# MB9BF52xT register map
File version: 1.0
Registers are 32-bit, read-write, reset 0x0 unless marked. A register's access mark holds for its fields unless they carry their own. Offsets are from the block's base; [hi:lo] are bit positions; {n}, {i} and the like mark numbered series; 'fields as' and 'values as' point back to an identical list.

## GPIO — peripheral GPIO
Base 0x40033000
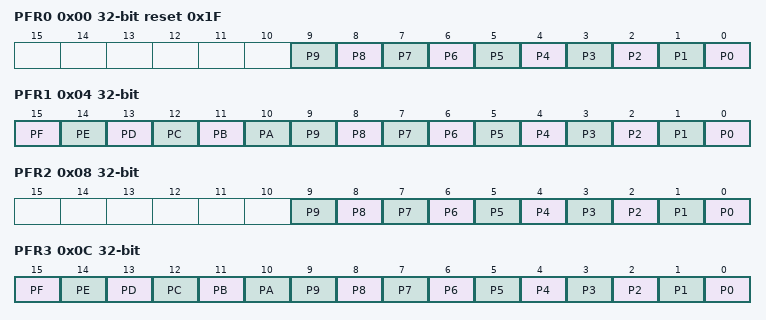
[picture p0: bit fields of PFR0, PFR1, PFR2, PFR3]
0x00 PFR0 reset 0x1F
  [n] P{n} (n=0..9)
0x04 PFR1
  [15] PF, [14] PE, [13] PD, [12] PC, [11] PB, [10] PA, [n] P{n} (n=0..9)
0x08 PFR2
  [n] P{n} (n=0..9)
0x0C PFR3
  fields as PFR1
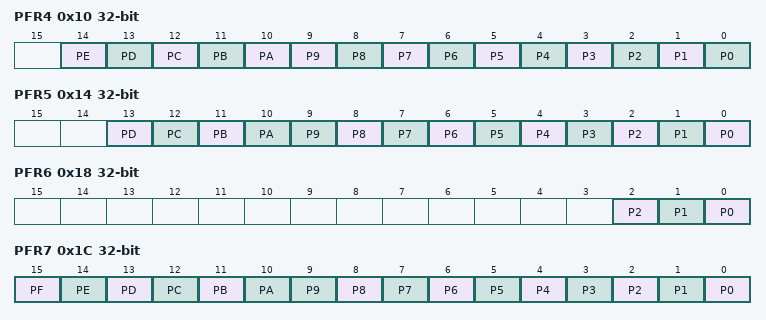
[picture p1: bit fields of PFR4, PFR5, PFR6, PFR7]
0x10 PFR4
  [14] PE, [13] PD, [12] PC, [11] PB, [10] PA, [n] P{n} (n=0..9)
0x14 PFR5
  [13] PD, [12] PC, [11] PB, [10] PA, [n] P{n} (n=0..9)
0x18 PFR6
  [2] P2, [1] P1, [0] P0
0x1C PFR7
  fields as PFR1
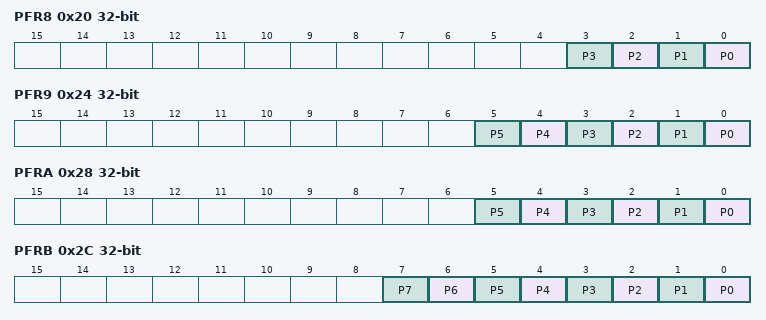
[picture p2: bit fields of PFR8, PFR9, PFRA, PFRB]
0x20 PFR8
  [n] P{n} (n=0..3)
0x24 PFR9
  [n] P{n} (n=0..5)
0x28 PFRA
  [n] P{n} (n=0..5)
0x2C PFRB
  [n] P{n} (n=0..7)
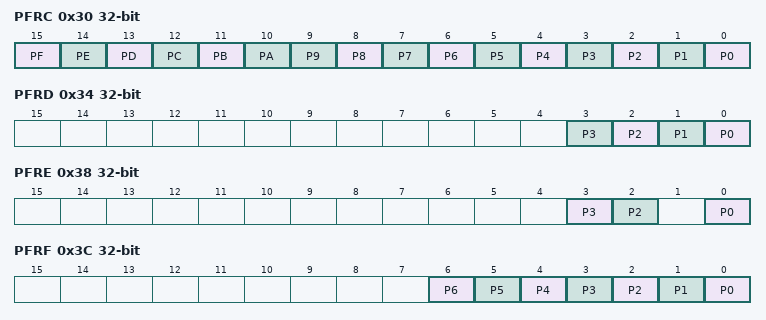
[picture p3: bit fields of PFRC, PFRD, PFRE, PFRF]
0x30 PFRC
  fields as PFR1
0x34 PFRD
  [n] P{n} (n=0..3)
0x38 PFRE (reset mask 0xB)
  [3] P3, [2] P2, [0] P0
0x3C PFRF
  [n] P{n} (n=0..6)
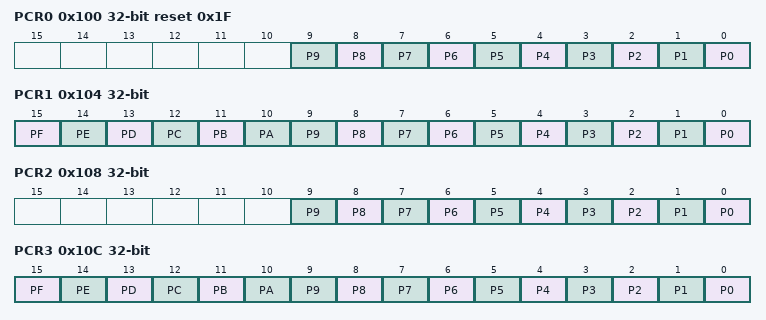
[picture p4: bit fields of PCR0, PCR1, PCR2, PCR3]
0x100 PCR0 reset 0x1F
  [n] P{n} (n=0..9)
0x104 PCR1
  fields as PFR1
0x108 PCR2
  [n] P{n} (n=0..9)
0x10C PCR3
  fields as PFR1
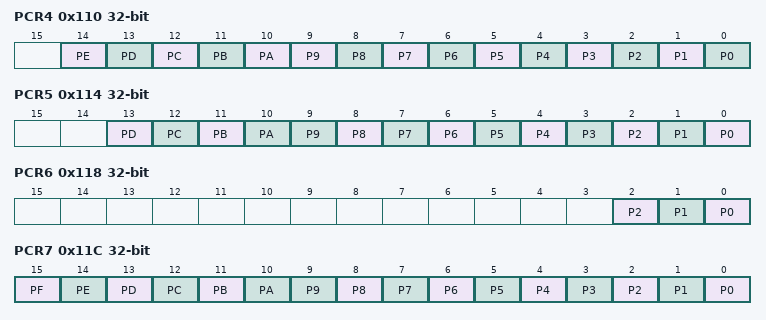
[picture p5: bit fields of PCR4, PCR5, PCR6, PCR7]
0x110 PCR4
  [14] PE, [13] PD, [12] PC, [11] PB, [10] PA, [n] P{n} (n=0..9)
0x114 PCR5
  [13] PD, [12] PC, [11] PB, [10] PA, [n] P{n} (n=0..9)
0x118 PCR6
  [2] P2, [1] P1, [0] P0
0x11C PCR7
  fields as PFR1
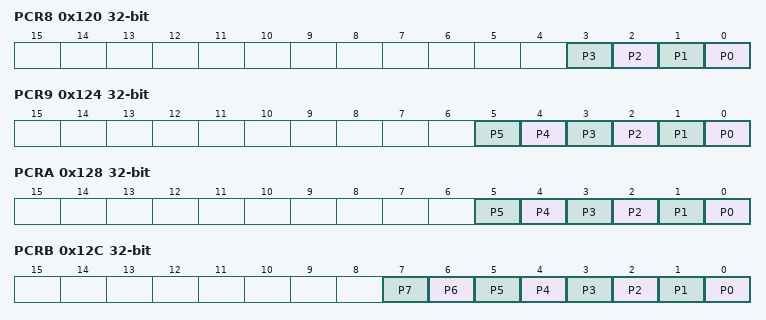
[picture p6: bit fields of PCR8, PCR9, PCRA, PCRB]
0x120 PCR8
  [n] P{n} (n=0..3)
0x124 PCR9
  [n] P{n} (n=0..5)
0x128 PCRA
  [n] P{n} (n=0..5)
0x12C PCRB
  [n] P{n} (n=0..7)
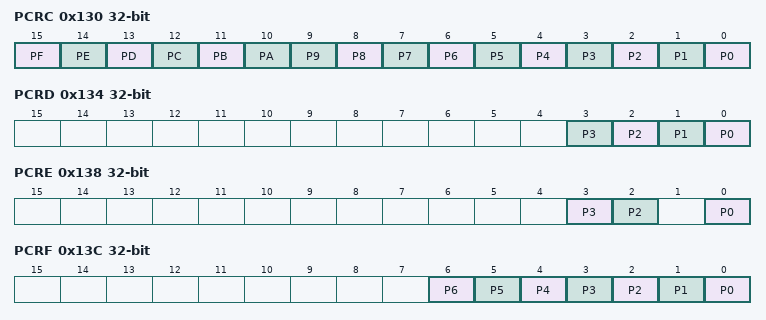
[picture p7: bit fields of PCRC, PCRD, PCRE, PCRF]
0x130 PCRC
  fields as PFR1
0x134 PCRD
  [n] P{n} (n=0..3)
0x138 PCRE (reset mask 0xB)
  [3] P3, [2] P2, [0] P0
0x13C PCRF
  [n] P{n} (n=0..6)
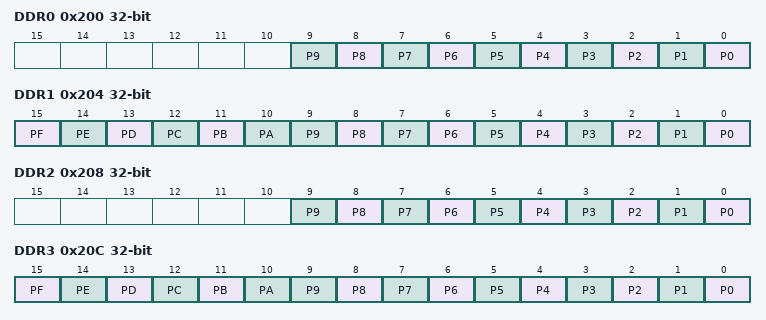
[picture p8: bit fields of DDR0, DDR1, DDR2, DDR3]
0x200 DDR0
  [n] P{n} (n=0..9)
0x204 DDR1
  fields as PFR1
0x208 DDR2
  [n] P{n} (n=0..9)
0x20C DDR3
  fields as PFR1
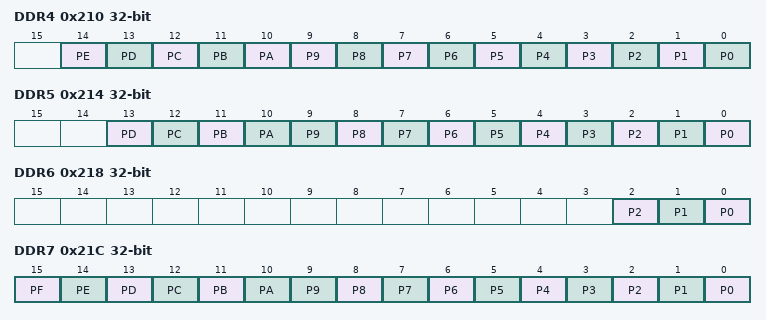
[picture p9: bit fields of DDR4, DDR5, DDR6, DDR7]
0x210 DDR4
  [14] PE, [13] PD, [12] PC, [11] PB, [10] PA, [n] P{n} (n=0..9)
0x214 DDR5
  [13] PD, [12] PC, [11] PB, [10] PA, [n] P{n} (n=0..9)
0x218 DDR6
  [2] P2, [1] P1, [0] P0
0x21C DDR7
  fields as PFR1
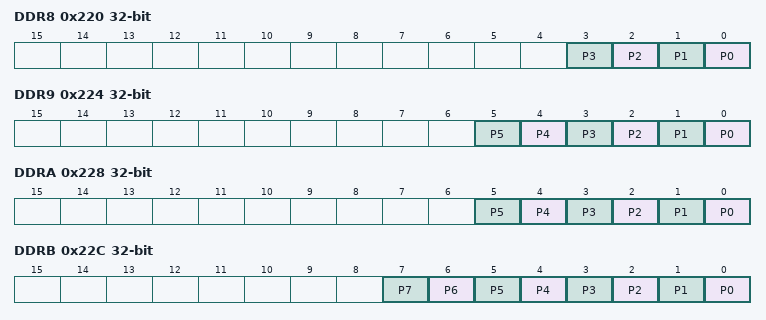
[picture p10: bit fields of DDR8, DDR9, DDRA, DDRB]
0x220 DDR8
  [n] P{n} (n=0..3)
0x224 DDR9
  [n] P{n} (n=0..5)
0x228 DDRA
  [n] P{n} (n=0..5)
0x22C DDRB
  [n] P{n} (n=0..7)
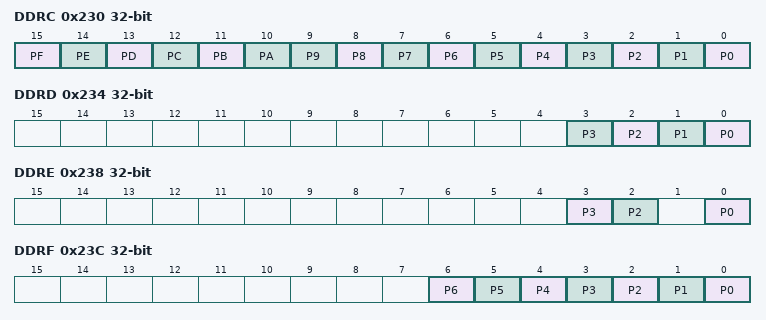
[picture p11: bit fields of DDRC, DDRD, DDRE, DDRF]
0x230 DDRC
  fields as PFR1
0x234 DDRD
  [n] P{n} (n=0..3)
0x238 DDRE (reset mask 0xB)
  [3] P3, [2] P2, [0] P0
0x23C DDRF
  [n] P{n} (n=0..6)
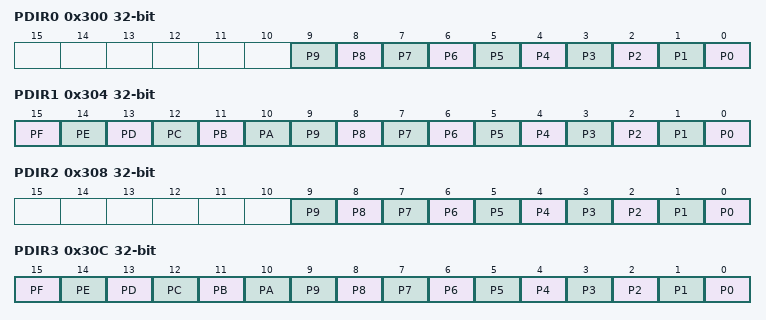
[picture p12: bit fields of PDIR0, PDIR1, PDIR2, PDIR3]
0x300 PDIR0
  [n] P{n} (n=0..9)
0x304 PDIR1
  fields as PFR1
0x308 PDIR2
  [n] P{n} (n=0..9)
0x30C PDIR3
  fields as PFR1
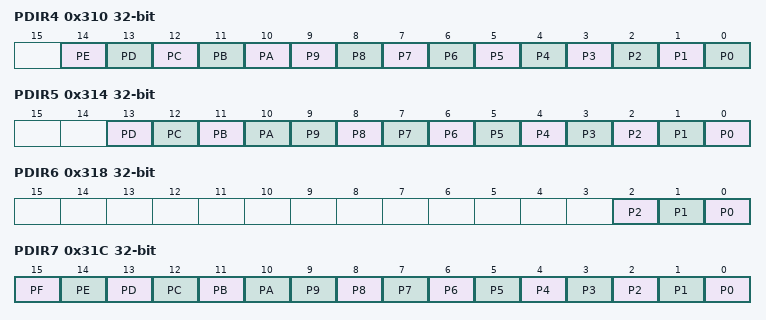
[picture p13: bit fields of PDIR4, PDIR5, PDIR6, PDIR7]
0x310 PDIR4
  [14] PE, [13] PD, [12] PC, [11] PB, [10] PA, [n] P{n} (n=0..9)
0x314 PDIR5
  [13] PD, [12] PC, [11] PB, [10] PA, [n] P{n} (n=0..9)
0x318 PDIR6
  [2] P2, [1] P1, [0] P0
0x31C PDIR7
  fields as PFR1
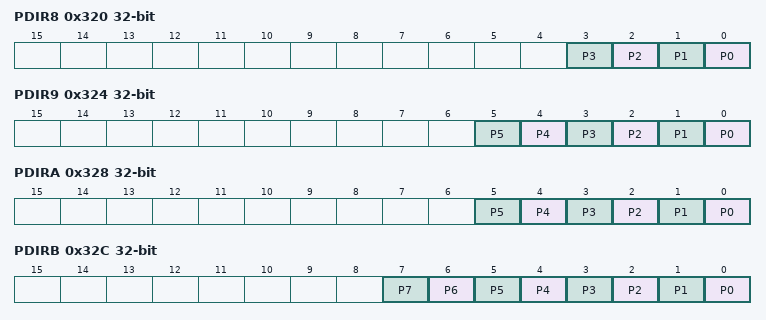
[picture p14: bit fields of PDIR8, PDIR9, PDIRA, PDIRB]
0x320 PDIR8
  [n] P{n} (n=0..3)
0x324 PDIR9
  [n] P{n} (n=0..5)
0x328 PDIRA
  [n] P{n} (n=0..5)
0x32C PDIRB
  [n] P{n} (n=0..7)
0x330 PDIRC
  fields as PFR1
0x334 PDIRD
  [n] P{n} (n=0..3)
0x338 PDIRE (reset mask 0xB)
  [3] P3, [2] P2, [0] P0
0x33C PDIRF
  [n] P{n} (n=0..6)
0x400 PDOR0
  [n] P{n} (n=0..9)
0x404 PDOR1
  fields as PFR1
0x408 PDOR2
  [n] P{n} (n=0..9)
0x40C PDOR3
  fields as PFR1
0x410 PDOR4
  [14] PE, [13] PD, [12] PC, [11] PB, [10] PA, [n] P{n} (n=0..9)
0x414 PDOR5
  [13] PD, [12] PC, [11] PB, [10] PA, [n] P{n} (n=0..9)
0x418 PDOR6
  [2] P2, [1] P1, [0] P0
0x41C PDOR7
  fields as PFR1
0x420 PDOR8
  [n] P{n} (n=0..3)
0x424 PDOR9
  [n] P{n} (n=0..5)
0x428 PDORA
  [n] P{n} (n=0..5)
0x42C PDORB
  [n] P{n} (n=0..7)
0x430 PDORC
  fields as PFR1
0x434 PDORD
  [n] P{n} (n=0..3)
0x438 PDORE (reset mask 0xB)
  [3] P3, [2] P2, [0] P0
0x43C PDORF
  [n] P{n} (n=0..6)
0x500 ADE reset 0xFFFFFFFF
  [n] AN{n} (n=0..31)
0x580 SPSR reset 0x5
  [4] USB0C, [3:2] MAINXC, [1:0] SUBXC
0x600 EPFR00 reset 0x30000 (reset mask 0x303002F7)
  [25] TRC1E, [24] TRC0E, [17] JTAGEN1S, [16] JTAGEN0B, [9] USBP0E, [7:6] SUBOUTE, [5:4] RTCCOE, [2:1] CROUTE, [0] NMIS
0x604 EPFR01
  [3n+22:3n+20] IC{n:02}S (n=0..3), [19:18] FRCK0S, [17:16] DTTI0S, [12] DTTI0C, [2n+1:2n] RTO{n:02}E (n=0..5)
0x608 EPFR02 reset not defined
0x60C EPFR03 reset not defined
0x610 EPFR04
  [29:28] TIOB3S, [8n+3:8n+2] TIOA{n}E (n=0..3), [25:24] TIOA3S, [21:20] TIOB2S, [13:12] TIOB1S, [9:8] TIOA1S, [6:4] TIOB0S
0x614 EPFR05
  [8n-27:8n-28] TIOB{n}S (n=4..7), [8n-29:8n-30] TIOA{n}E (n=4..7), [25:24] TIOA7S, [9:8] TIOA5S
0x618 EPFR06
  [2n+1:2n] EINT{n:02}S (n=0..15)
0x61C EPFR07
  [6n+9:6n+8] SCK{n}B (n=0..3), [6n+7:6n+6] SOT{n}B (n=0..3), [6n+5:6n+4] SIN{n}S (n=0..3)
0x620 EPFR08
  [6n-15:6n-16] SCK{n}B (n=4..7), [6n-17:6n-18] SOT{n}B (n=4..7), [6n-19:6n-20] SIN{n}S (n=4..7), [3:2] CTS4S, [1:0] RTS4E
0x624 EPFR09
  [27:26] CTX0E, [25:24] CRX0S, [19:16] ADTRG1S, [15:12] ADTRG0S, [11:10] QZIN1S, [9:8] QBIN1S, [7:6] QAIN1S, [5:4] QZIN0S, [3:2] QBIN0S, [1:0] QAIN0S
0x628 EPFR10
  [n+7] UEA{n:02}E (n=8..24), [14] UEAOOE, [n+6] UECS{n}E (n=1..7), [6] UEFLSE, [5] UEOEXE, [4] UEDQME, [3] UEWEXE, [2] UECLKE, [1] UEDTHB, [0] UEDEFB
0x62C EPFR11
  [25] UERLC, [n+9] UED{n:02}B (n=0..15), [n+1] UEA{n:02}E (n=1..7), [1] UECS0E, [0] UEALEE
0x630 EPFR12
  [8n-59:8n-60] TIOB{n}S (n=8..11), [8n-61:8n-62] TIOA{n}E (n=8..11), [25:24] TIOA11S, [9:8] TIOA9S
0x634 EPFR13
  [8n-91:8n-92] TIOB{n}S (n=12..15), [8n-93:8n-94] TIOA{n}E (n=12..15), [25:24] TIOA15S, [9:8] TIOA13S
0x638 EPFR14 reset not defined
0x63C EPFR15
  [2n-31:2n-32] EINT{n}S (n=16..31)
0x640 EPFR16
  [6n-39:6n-40] SCK{n}B (n=8..11), [6n-41:6n-42] SOT{n}B (n=8..11), [6n-43:6n-44] SIN{n}S (n=8..11)
0x644 EPFR17
  [6n-63:6n-64] SCK{n}B (n=12..15), [6n-65:6n-66] SOT{n}B (n=12..15), [6n-67:6n-68] SIN{n}S (n=12..15)
0x648 EPFR18
  [3:2] CECR1B, [1:0] CECR0B
0x700 PZR0
  [n] P{n} (n=0..9)
0x704 PZR1
  fields as PFR1
0x708 PZR2
  [n] P{n} (n=0..9)
0x70C PZR3
  fields as PFR1
0x710 PZR4
  [14] PE, [13] PD, [12] PC, [11] PB, [10] PA, [n] P{n} (n=0..9)
0x714 PZR5
  [13] PD, [12] PC, [11] PB, [10] PA, [n] P{n} (n=0..9)
0x718 PZR6
  [2] P2, [1] P1, [0] P0
0x71C PZR7
  fields as PFR1
0x720 PZR8
  [n] P{n} (n=0..3)
0x724 PZR9
  [n] P{n} (n=0..5)
0x728 PZRA
  [n] P{n} (n=0..5)
0x72C PZRB
  [n] P{n} (n=0..7)
0x730 PZRC
  fields as PFR1
0x734 PZRD
  [n] P{n} (n=0..3)
0x738 PZRE (reset mask 0xB)
  [3] P3, [2] P2, [0] P0
0x73C PZRF
  [n] P{n} (n=0..6)
